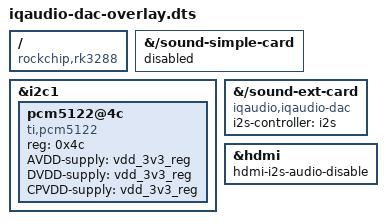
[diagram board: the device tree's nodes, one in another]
/dts-v1/;
/plugin/;

/ {
	compatible = "rockchip,rk3288";

	fragment@0 {
		target-path ="/sound-simple-card";
		__overlay__ {
			status = "disabled";
		};
	};

	fragment@1 {
		target = <&i2c1>;
		__overlay__ {
			#address-cells = <1>;
			#size-cells = <0>;
			status = "okay";

			pcm5122@4c {
				#sound-dai-cells = <0>;
				compatible = "ti,pcm5122";
				reg = <0x4c>;
				AVDD-supply = <&vdd_3v3_reg>;
				DVDD-supply = <&vdd_3v3_reg>;
				CPVDD-supply = <&vdd_3v3_reg>;
				status = "okay";
			};
		};
	};

	fragment@2 {
		target-path = "/sound-ext-card";
		frag2: __overlay__ {
			compatible = "iqaudio,iqaudio-dac";
			i2s-controller = <&i2s>;
			status = "okay";
		};
	};

	fragment@3 {
		target = <&hdmi>;
		__overlay__ {
			hdmi-i2s-audio-disable;
		};
	};

	__overrides__ {
		24db_digital_gain = <&frag2>,"iqaudio,24db_digital_gain?";
	};
};
